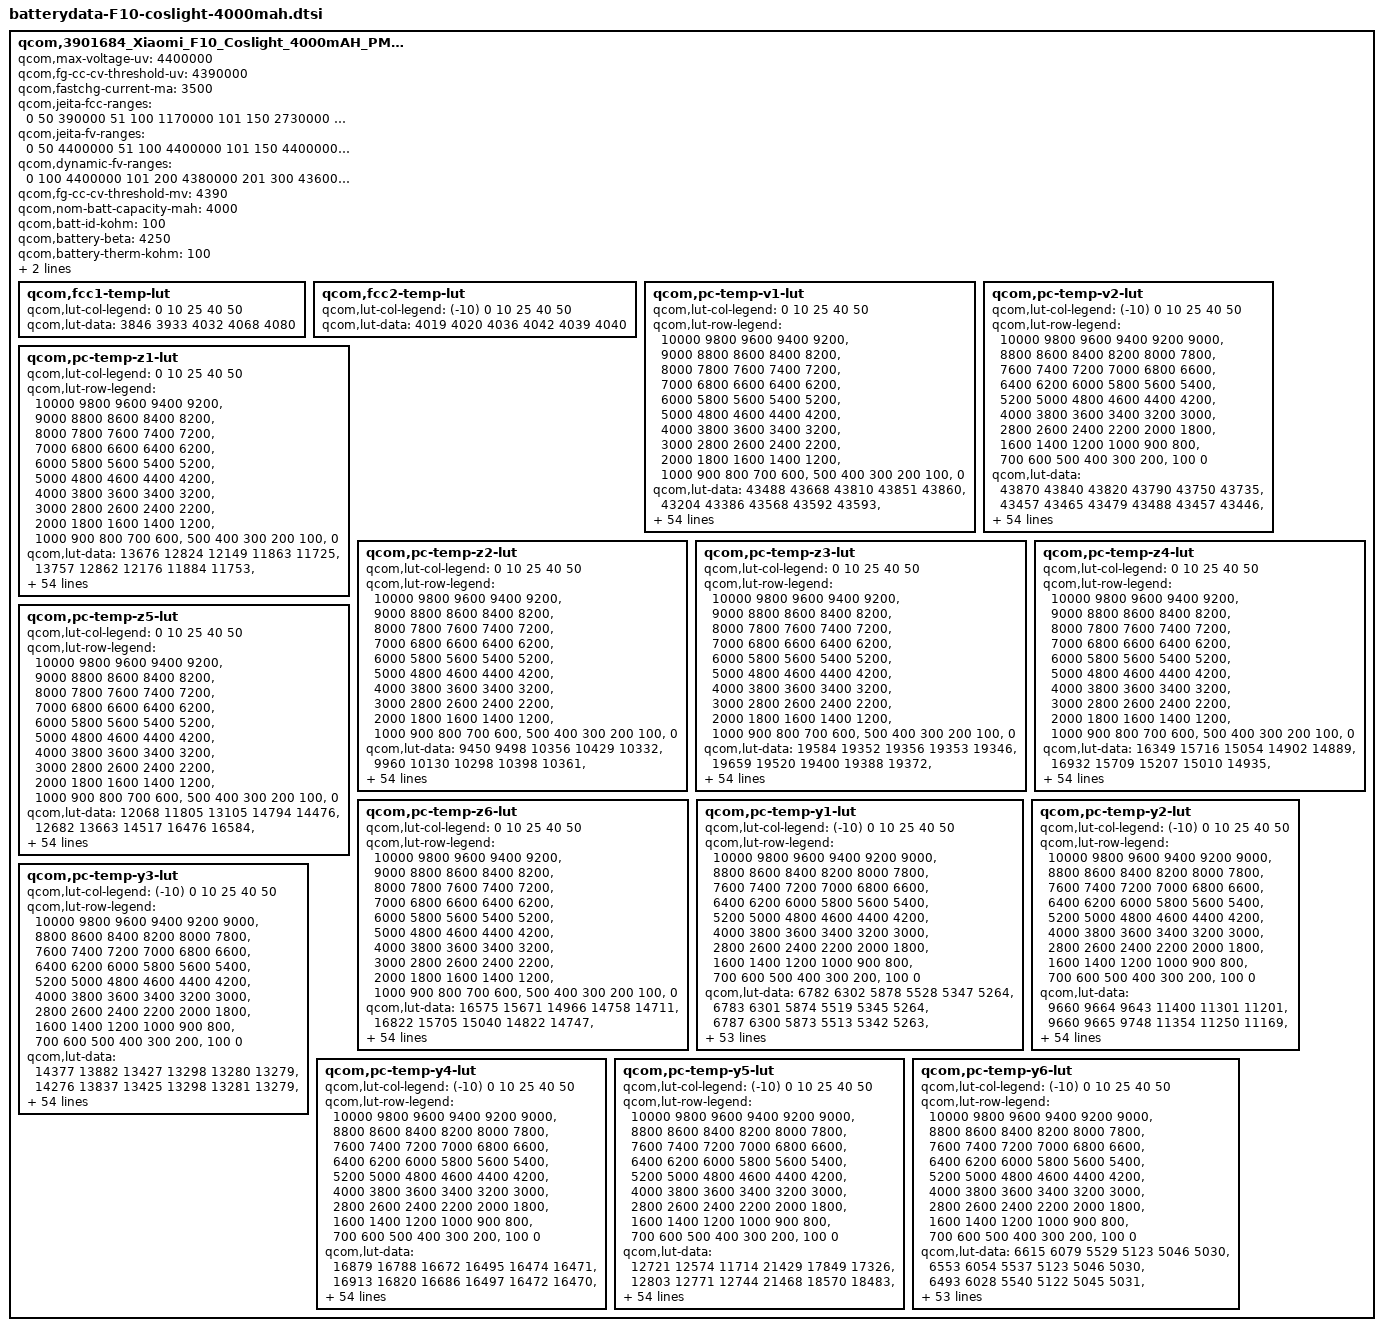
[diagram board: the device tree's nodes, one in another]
qcom,3901684_Xiaomi_F10_Coslight_4000mAH_PM7150 {
    /* 3901684_Xiaomi_F10_Coslight_4000mAH_PM7150_averaged_MasterSlave_Mar20th2019 */
	qcom,max-voltage-uv = <4400000>;
	qcom,fg-cc-cv-threshold-uv = <4390000>;
	qcom,fastchg-current-ma = <3500>;
	qcom,jeita-fcc-ranges = <0  50  390000
				51  100  1170000
				101 150  2730000
				151 450  3500000
				451 580  1950000>;
	qcom,jeita-fv-ranges = <0   50  4400000
				51  100  4400000
				101 150  4400000
				151 450  4400000
				451 580  4100000>;
	qcom,dynamic-fv-ranges = <0    100  4400000
				  101  200  4380000
				  201  300  4360000
				  301  400  4340000
				  401  500  4340000>;
	qcom,fg-cc-cv-threshold-mv = <4390>;
	qcom,nom-batt-capacity-mah = <4000>;
    qcom,batt-id-kohm = <100>;
	qcom,battery-beta = <4250>;
	qcom,battery-therm-kohm = <100>;
	qcom,battery-type = "f10_coslt";
	qcom,qg-batt-profile-ver = <100>;

	qcom,fcc1-temp-lut {
		qcom,lut-col-legend = <0 10 25 40 50>;
		qcom,lut-data = <3846 3933 4032 4068 4080>;
	};

	qcom,fcc2-temp-lut {
		qcom,lut-col-legend = <(-10) 0 10 25 40 50>;
		qcom,lut-data = <4019 4020 4036 4042 4039 4040>;
	};

	qcom,pc-temp-v1-lut {
		qcom,lut-col-legend = <0 10 25 40 50>;
		qcom,lut-row-legend = <10000 9800 9600 9400 9200>,
			<9000 8800 8600 8400 8200>,
			<8000 7800 7600 7400 7200>,
			<7000 6800 6600 6400 6200>,
			<6000 5800 5600 5400 5200>,
			<5000 4800 4600 4400 4200>,
			<4000 3800 3600 3400 3200>,
			<3000 2800 2600 2400 2200>,
			<2000 1800 1600 1400 1200>,
			<1000 900 800 700 600>,
			<500 400 300 200 100>,
			<0>;
		qcom,lut-data = <43488 43668 43810 43851 43860>,
			<43204 43386 43568 43592 43593>,
			<42945 43123 43311 43350 43352>,
			<42701 42877 43059 43112 43117>,
			<42462 42641 42816 42873 42880>,
			<42232 42405 42577 42634 42643>,
			<42008 42173 42339 42398 42407>,
			<41791 41948 42102 42164 42173>,
			<41583 41727 41871 41932 41942>,
			<41392 41514 41644 41702 41714>,
			<41221 41322 41424 41473 41488>,
			<41034 41147 41220 41251 41267>,
			<40791 40954 41030 41034 41048>,
			<40521 40708 40828 40824 40836>,
			<40287 40448 40590 40620 40631>,
			<40082 40232 40355 40424 40434>,
			<39904 40042 40169 40238 40245>,
			<39761 39879 40009 40063 40067>,
			<39639 39743 39857 39894 39896>,
			<39519 39621 39716 39738 39740>,
			<39396 39491 39567 39584 39588>,
			<39275 39356 39372 39388 39398>,
			<39158 39214 39137 39126 39135>,
			<39043 39048 38932 38904 38905>,
			<38935 38866 38758 38764 38769>,
			<38832 38707 38620 38654 38663>,
			<38733 38559 38531 38556 38559>,
			<38640 38442 38465 38470 38456>,
			<38550 38365 38402 38388 38365>,
			<38468 38305 38338 38306 38285>,
			<38396 38261 38279 38231 38214>,
			<38330 38230 38225 38166 38147>,
			<38286 38202 38175 38110 38085>,
			<38262 38174 38127 38057 38026>,
			<38242 38149 38084 38008 37972>,
			<38212 38120 38042 37960 37919>,
			<38172 38091 38003 37913 37866>,
			<38126 38056 37963 37866 37813>,
			<38071 38006 37909 37804 37745>,
			<38004 37936 37827 37716 37652>,
			<37920 37851 37728 37612 37543>,
			<37805 37742 37612 37504 37433>,
			<37672 37611 37477 37380 37309>,
			<37517 37451 37322 37226 37149>,
			<37364 37299 37182 37088 37017>,
			<37251 37194 37084 36995 36937>,
			<37212 37155 37052 36969 36910>,
			<37178 37125 37037 36946 36888>,
			<37148 37101 37015 36926 36869>,
			<37099 37057 36972 36878 36809>,
			<36922 36861 36756 36633 36536>,
			<36490 36427 36327 36199 36099>,
			<35920 35855 35755 35625 35525>,
			<35147 35075 34970 34840 34741>,
			<33910 33851 33747 33621 33517>,
			<30000 30000 30000 30000 30000>;
	};

	qcom,pc-temp-v2-lut {
		qcom,lut-col-legend = <(-10) 0 10 25 40 50>;
		qcom,lut-row-legend = <10000 9800 9600 9400 9200 9000>,
			<8800 8600 8400 8200 8000 7800>,
			<7600 7400 7200 7000 6800 6600>,
			<6400 6200 6000 5800 5600 5400>,
			<5200 5000 4800 4600 4400 4200>,
			<4000 3800 3600 3400 3200 3000>,
			<2800 2600 2400 2200 2000 1800>,
			<1600 1400 1200 1000 900 800>,
			<700 600 500 400 300 200>,
			<100 0>;
		qcom,lut-data = <43870 43840 43820 43790 43750 43735>,
			<43457 43465 43479 43488 43457 43446>,
			<43083 43120 43164 43203 43180 43174>,
			<42755 42809 42879 42939 42922 42918>,
			<42466 42530 42622 42694 42681 42679>,
			<42199 42266 42374 42454 42445 42444>,
			<41950 42011 42125 42215 42209 42207>,
			<41717 41769 41882 41979 41974 41972>,
			<41486 41534 41646 41748 41743 41741>,
			<41254 41301 41414 41521 41515 41514>,
			<41060 41106 41197 41298 41292 41290>,
			<40933 40978 41007 41082 41075 41070>,
			<40811 40857 40821 40869 40862 40854>,
			<40558 40626 40599 40660 40656 40649>,
			<40083 40219 40341 40451 40453 40448>,
			<39699 39874 40110 40251 40259 40256>,
			<39494 39664 39930 40057 40075 40071>,
			<39331 39489 39759 39874 39898 39893>,
			<39161 39308 39564 39714 39732 39726>,
			<38993 39127 39353 39572 39575 39571>,
			<38836 38956 39146 39401 39399 39397>,
			<38687 38791 38939 39162 39176 39180>,
			<38551 38638 38746 38920 38951 38960>,
			<38437 38500 38588 38739 38766 38774>,
			<38339 38375 38451 38586 38602 38607>,
			<38253 38271 38330 38457 38467 38470>,
			<38176 38189 38219 38348 38358 38359>,
			<38106 38119 38125 38252 38263 38261>,
			<38039 38057 38054 38163 38175 38171>,
			<37975 38002 37996 38081 38096 38087>,
			<37913 37951 37943 38008 38025 38015>,
			<37851 37902 37895 37940 37962 37951>,
			<37791 37854 37850 37878 37901 37890>,
			<37730 37806 37806 37824 37837 37825>,
			<37671 37759 37763 37775 37772 37756>,
			<37613 37710 37716 37724 37700 37675>,
			<37556 37657 37665 37673 37619 37573>,
			<37499 37600 37608 37616 37534 37472>,
			<37443 37536 37543 37547 37455 37389>,
			<37388 37466 37471 37468 37376 37314>,
			<37331 37387 37389 37380 37293 37234>,
			<37272 37293 37292 37280 37206 37151>,
			<37209 37190 37188 37162 37094 37039>,
			<37139 37086 37078 37031 36957 36896>,
			<37057 36996 36968 36923 36855 36802>,
			<36948 36906 36845 36854 36804 36754>,
			<36887 36876 36802 36838 36794 36743>,
			<36813 36823 36763 36818 36777 36726>,
			<36723 36763 36717 36783 36745 36693>,
			<36595 36669 36638 36690 36640 36571>,
			<36369 36466 36437 36389 36312 36217>,
			<36002 36054 36001 35863 35794 35699>,
			<35445 35432 35359 35185 35122 35015>,
			<34591 34546 34467 34229 34190 34081>,
			<33142 33098 33118 32916 32929 32822>,
			<28835 28221 27917 27830 28084 28065>;
	};

	qcom,pc-temp-z1-lut {
		qcom,lut-col-legend = <0 10 25 40 50>;
		qcom,lut-row-legend = <10000 9800 9600 9400 9200>,
			<9000 8800 8600 8400 8200>,
			<8000 7800 7600 7400 7200>,
			<7000 6800 6600 6400 6200>,
			<6000 5800 5600 5400 5200>,
			<5000 4800 4600 4400 4200>,
			<4000 3800 3600 3400 3200>,
			<3000 2800 2600 2400 2200>,
			<2000 1800 1600 1400 1200>,
			<1000 900 800 700 600>,
			<500 400 300 200 100>,
			<0>;
		qcom,lut-data = <13676 12824 12149 11863 11725>,
			<13757 12862 12176 11884 11753>,
			<13750 12873 12181 11877 11749>,
			<13740 12865 12182 11863 11738>,
			<13721 12854 12172 11851 11729>,
			<13690 12851 12156 11840 11719>,
			<13677 12847 12147 11833 11712>,
			<13679 12840 12141 11827 11706>,
			<13682 12823 12138 11823 11701>,
			<13676 12805 12140 11819 11699>,
			<13643 12798 12143 11816 11697>,
			<13602 12796 12143 11816 11697>,
			<13561 12791 12143 11815 11698>,
			<13514 12763 12140 11815 11699>,
			<13485 12734 12125 11815 11700>,
			<13464 12731 12111 11817 11701>,
			<13451 12737 12114 11819 11702>,
			<13442 12744 12126 11821 11706>,
			<13420 12757 12136 11823 11709>,
			<13410 12773 12143 11826 11711>,
			<13430 12782 12147 11829 11713>,
			<13452 12789 12149 11833 11715>,
			<13457 12794 12149 11837 11717>,
			<13462 12802 12149 11839 11719>,
			<13467 12813 12147 11840 11722>,
			<13470 12818 12146 11841 11724>,
			<13473 12819 12152 11843 11728>,
			<13476 12820 12166 11849 11732>,
			<13480 12824 12172 11854 11737>,
			<13486 12829 12171 11859 11742>,
			<13491 12835 12170 11864 11746>,
			<13497 12842 12170 11869 11751>,
			<13507 12850 12172 11876 11757>,
			<13534 12865 12175 11881 11762>,
			<13560 12886 12183 11887 11769>,
			<13561 12897 12191 11893 11776>,
			<13549 12904 12198 11899 11781>,
			<13541 12912 12206 11906 11785>,
			<13554 12920 12211 11909 11790>,
			<13582 12930 12215 11912 11797>,
			<13611 12938 12218 11914 11802>,
			<13651 12943 12227 11919 11805>,
			<13680 12949 12236 11926 11808>,
			<13698 12961 12242 11928 11811>,
			<13664 12976 12249 11931 11816>,
			<13665 12976 12271 11939 11820>,
			<13661 12955 12257 11939 11820>,
			<13647 12969 12248 11936 11820>,
			<13654 12983 12270 11940 11823>,
			<13680 12977 12269 11953 11834>,
			<13683 12995 12281 11963 11839>,
			<13680 13009 12271 11965 11851>,
			<13730 13048 12310 11977 11861>,
			<13762 13082 12328 11996 11885>,
			<13762 13082 12328 11996 11885>,
			<13762 13082 12328 11996 11885>;
	};

	qcom,pc-temp-z2-lut {
		qcom,lut-col-legend = <0 10 25 40 50>;
		qcom,lut-row-legend = <10000 9800 9600 9400 9200>,
			<9000 8800 8600 8400 8200>,
			<8000 7800 7600 7400 7200>,
			<7000 6800 6600 6400 6200>,
			<6000 5800 5600 5400 5200>,
			<5000 4800 4600 4400 4200>,
			<4000 3800 3600 3400 3200>,
			<3000 2800 2600 2400 2200>,
			<2000 1800 1600 1400 1200>,
			<1000 900 800 700 600>,
			<500 400 300 200 100>,
			<0>;
		qcom,lut-data = <9450 9498 10356 10429 10332>,
			<9960 10130 10298 10398 10361>,
			<10130 10317 10438 10460 10380>,
			<10228 10298 10522 10512 10414>,
			<10231 10268 10495 10503 10430>,
			<10214 10239 10448 10467 10425>,
			<10198 10209 10409 10424 10408>,
			<10180 10191 10369 10366 10380>,
			<10164 10182 10349 10323 10352>,
			<10163 10177 10347 10331 10342>,
			<10170 10189 10349 10366 10333>,
			<10175 10269 10356 10386 10328>,
			<10164 10324 10371 10396 10332>,
			<10142 10280 10388 10403 10337>,
			<10136 10208 10423 10409 10330>,
			<10214 10194 10460 10415 10305>,
			<10301 10211 10471 10413 10292>,
			<10279 10235 10476 10394 10292>,
			<10174 10266 10484 10380 10299>,
			<10109 10302 10500 10390 10317>,
			<10097 10330 10523 10420 10351>,
			<10090 10354 10554 10483 10426>,
			<10088 10372 10591 10650 10668>,
			<10087 10385 10600 10752 10839>,
			<10087 10394 10566 10630 10700>,
			<10093 10395 10528 10442 10449>,
			<10105 10395 10517 10422 10425>,
			<10119 10397 10510 10482 10589>,
			<10140 10410 10509 10516 10690>,
			<10162 10432 10514 10505 10563>,
			<10181 10444 10521 10483 10369>,
			<10199 10448 10523 10453 10302>,
			<10194 10452 10523 10411 10272>,
			<9887 10459 10526 10396 10259>,
			<9517 10470 10538 10404 10253>,
			<9481 10484 10554 10422 10253>,
			<9559 10506 10573 10452 10281>,
			<9652 10526 10596 10505 10363>,
			<9790 10500 10620 10551 10423>,
			<9948 10408 10646 10592 10461>,
			<9986 10370 10669 10619 10482>,
			<9963 10383 10689 10624 10476>,
			<9939 10358 10701 10620 10464>,
			<9914 10295 10685 10590 10500>,
			<9800 12043 10702 10572 10499>,
			<9756 15846 10733 10546 10435>,
			<9764 13719 10726 10542 10447>,
			<9771 14156 10705 10558 10467>,
			<9740 15920 10736 10601 10544>,
			<9733 15952 10790 10756 10632>,
			<9673 13590 10784 10574 10420>,
			<9525 12191 10699 10408 10277>,
			<9456 11187 10615 10352 10215>,
			<9398 10638 10493 10293 10167>,
			<9398 10638 10493 10293 10167>,
			<9398 10638 10493 10293 10167>;
	};

	qcom,pc-temp-z3-lut {
		qcom,lut-col-legend = <0 10 25 40 50>;
		qcom,lut-row-legend = <10000 9800 9600 9400 9200>,
			<9000 8800 8600 8400 8200>,
			<8000 7800 7600 7400 7200>,
			<7000 6800 6600 6400 6200>,
			<6000 5800 5600 5400 5200>,
			<5000 4800 4600 4400 4200>,
			<4000 3800 3600 3400 3200>,
			<3000 2800 2600 2400 2200>,
			<2000 1800 1600 1400 1200>,
			<1000 900 800 700 600>,
			<500 400 300 200 100>,
			<0>;
		qcom,lut-data = <19584 19352 19356 19353 19346>,
			<19659 19520 19400 19388 19372>,
			<19680 19596 19446 19401 19385>,
			<19689 19617 19467 19408 19394>,
			<19672 19626 19470 19414 19402>,
			<19620 19626 19472 19419 19410>,
			<19593 19624 19473 19421 19413>,
			<19592 19621 19474 19418 19411>,
			<19592 19616 19474 19414 19408>,
			<19593 19609 19469 19410 19404>,
			<19598 19604 19461 19406 19398>,
			<19605 19596 19452 19403 19393>,
			<19619 19590 19442 19401 19390>,
			<19639 19577 19437 19399 19387>,
			<19654 19557 19438 19395 19384>,
			<19672 19543 19438 19389 19380>,
			<19685 19534 19434 19384 19376>,
			<19669 19523 19424 19380 19372>,
			<19620 19503 19417 19376 19367>,
			<19594 19483 19413 19372 19362>,
			<19594 19480 19411 19369 19356>,
			<19597 19484 19415 19370 19356>,
			<19602 19488 19425 19382 19369>,
			<19614 19498 19429 19390 19378>,
			<19621 19514 19426 19381 19369>,
			<19623 19519 19421 19366 19352>,
			<19625 19520 19419 19365 19356>,
			<19625 19519 19417 19373 19394>,
			<19626 19519 19417 19382 19418>,
			<19626 19520 19420 19396 19413>,
			<19625 19519 19423 19408 19403>,
			<19618 19514 19425 19408 19396>,
			<19602 19508 19427 19401 19389>,
			<19467 19502 19427 19395 19382>,
			<19308 19496 19425 19388 19374>,
			<19277 19490 19423 19381 19366>,
			<19271 19485 19418 19375 19359>,
			<19268 19479 19413 19369 19353>,
			<19265 19452 19409 19367 19351>,
			<19263 19394 19406 19367 19352>,
			<19262 19366 19404 19367 19353>,
			<19263 19306 19403 19366 19354>,
			<19263 19262 19402 19364 19355>,
			<19263 19262 19399 19364 19361>,
			<19264 19259 19391 19362 19360>,
			<19264 19257 19381 19355 19350>,
			<19264 19257 19382 19346 19341>,
			<19264 19257 19359 19344 19336>,
			<19264 19257 19354 19340 19323>,
			<19264 19257 19351 19325 19320>,
			<19265 19257 19355 19350 19350>,
			<19269 19258 19360 19361 19360>,
			<19271 19259 19357 19362 19362>,
			<19273 19260 19359 19361 19356>,
			<19273 19260 19359 19361 19356>,
			<19273 19260 19359 19361 19356>;
	};

	qcom,pc-temp-z4-lut {
		qcom,lut-col-legend = <0 10 25 40 50>;
		qcom,lut-row-legend = <10000 9800 9600 9400 9200>,
			<9000 8800 8600 8400 8200>,
			<8000 7800 7600 7400 7200>,
			<7000 6800 6600 6400 6200>,
			<6000 5800 5600 5400 5200>,
			<5000 4800 4600 4400 4200>,
			<4000 3800 3600 3400 3200>,
			<3000 2800 2600 2400 2200>,
			<2000 1800 1600 1400 1200>,
			<1000 900 800 700 600>,
			<500 400 300 200 100>,
			<0>;
		qcom,lut-data = <16349 15716 15054 14902 14889>,
			<16932 15709 15207 15010 14935>,
			<16706 15677 15124 14968 14917>,
			<16405 15498 15032 14902 14871>,
			<16187 15279 14958 14858 14836>,
			<15992 15152 14891 14822 14807>,
			<15824 15056 14842 14794 14782>,
			<15675 14980 14803 14770 14757>,
			<15542 14921 14773 14751 14738>,
			<15426 14872 14750 14737 14730>,
			<15322 14823 14732 14726 14726>,
			<15232 14770 14719 14717 14722>,
			<15158 14740 14709 14710 14717>,
			<15096 14739 14705 14705 14711>,
			<15034 14745 14707 14701 14707>,
			<14957 14742 14709 14698 14704>,
			<14895 14736 14706 14694 14700>,
			<14881 14732 14695 14689 14695>,
			<14889 14729 14684 14683 14691>,
			<14890 14726 14675 14677 14685>,
			<14871 14721 14669 14673 14679>,
			<14845 14708 14687 14684 14686>,
			<14821 14700 14744 14756 14754>,
			<14797 14711 14791 14811 14811>,
			<14778 14738 14827 14823 14820>,
			<14766 14759 14849 14829 14824>,
			<14757 14791 14841 14824 14815>,
			<14751 14811 14814 14796 14759>,
			<14747 14807 14789 14765 14717>,
			<14744 14792 14768 14737 14708>,
			<14743 14776 14749 14712 14702>,
			<14743 14757 14732 14700 14696>,
			<14748 14738 14716 14693 14690>,
			<14879 14723 14706 14689 14686>,
			<15037 14710 14699 14687 14685>,
			<15057 14700 14694 14686 14684>,
			<15042 14691 14690 14684 14682>,
			<15027 14685 14686 14681 14680>,
			<15015 14706 14686 14680 14680>,
			<15003 14765 14688 14687 14689>,
			<14995 14791 14690 14694 14698>,
			<14990 14849 14688 14690 14693>,
			<14984 14892 14685 14682 14683>,
			<14973 14889 14684 14683 14686>,
			<14915 14861 14675 14677 14680>,
			<14896 14837 14658 14658 14657>,
			<14892 14830 14648 14656 14655>,
			<14886 14824 14657 14644 14644>,
			<14878 14815 14651 14631 14635>,
			<14873 14811 14650 14638 14629>,
			<14874 14821 14664 14644 14646>,
			<14903 14843 14674 14650 14653>,
			<14923 14854 14683 14655 14659>,
			<14946 14870 14688 14663 14671>,
			<14946 14870 14688 14663 14671>,
			<14946 14870 14688 14663 14671>;
	};

	qcom,pc-temp-z5-lut {
		qcom,lut-col-legend = <0 10 25 40 50>;
		qcom,lut-row-legend = <10000 9800 9600 9400 9200>,
			<9000 8800 8600 8400 8200>,
			<8000 7800 7600 7400 7200>,
			<7000 6800 6600 6400 6200>,
			<6000 5800 5600 5400 5200>,
			<5000 4800 4600 4400 4200>,
			<4000 3800 3600 3400 3200>,
			<3000 2800 2600 2400 2200>,
			<2000 1800 1600 1400 1200>,
			<1000 900 800 700 600>,
			<500 400 300 200 100>,
			<0>;
		qcom,lut-data = <12068 11805 13105 14794 14476>,
			<12682 13663 14517 16476 16584>,
			<13059 14803 16164 17427 17425>,
			<13339 15366 17399 18166 18528>,
			<13521 15816 18166 19089 19689>,
			<13671 16354 18845 20011 20860>,
			<13821 16934 19850 20564 21968>,
			<14032 17605 21219 20921 23164>,
			<14296 18400 22511 21323 24051>,
			<14526 19246 23717 22058 24084>,
			<14722 20355 24682 23149 23878>,
			<14977 22381 25011 24202 23807>,
			<15447 23829 25072 25332 24409>,
			<16055 24330 25398 26277 25312>,
			<16684 24777 28353 26744 25951>,
			<18399 25088 31787 26886 26556>,
			<20005 25071 31433 26861 27134>,
			<19477 24647 29122 27312 27751>,
			<17227 22780 28219 28003 28165>,
			<16028 20648 30088 28951 28372>,
			<16307 20698 33450 30371 28789>,
			<16872 22949 39426 32478 29794>,
			<17731 26251 48734 36284 32673>,
			<19374 35028 51577 38412 34634>,
			<21171 48727 43042 31788 29235>,
			<22986 53682 32940 21734 19795>,
			<25142 52124 28773 19776 18837>,
			<27702 49566 26042 19634 24638>,
			<31349 48095 25391 19762 28758>,
			<33917 46489 25900 23615 29254>,
			<34214 44620 26850 29088 29587>,
			<34319 41836 28704 31752 30507>,
			<33970 39347 31933 33664 32360>,
			<24494 38187 35347 34897 33251>,
			<13047 37314 39698 35771 33141>,
			<11330 36519 42444 36291 32872>,
			<11293 35785 42135 35950 32238>,
			<11280 34945 41098 34863 30963>,
			<11283 32441 39932 34083 30210>,
			<11292 27797 38401 33668 29975>,
			<11306 25841 36924 33125 29744>,
			<11357 17804 35863 30938 29041>,
			<11396 11760 34701 28209 28242>,
			<11420 11783 32202 28711 31717>,
			<11663 11863 31291 28853 32969>,
			<11696 11770 30257 27411 27639>,
			<11631 11755 32521 22995 22679>,
			<11593 11707 21689 24268 23072>,
			<11588 11640 21033 26370 21154>,
			<11606 11672 21179 20038 21192>,
			<11676 11783 19812 26887 31299>,
			<11747 11696 18623 25719 28100>,
			<11603 11583 17171 23479 24321>,
			<11481 11457 16600 20465 18831>,
			<11481 11457 16600 20465 18831>,
			<11481 11457 16600 20465 18831>;
	};

	qcom,pc-temp-z6-lut {
		qcom,lut-col-legend = <0 10 25 40 50>;
		qcom,lut-row-legend = <10000 9800 9600 9400 9200>,
			<9000 8800 8600 8400 8200>,
			<8000 7800 7600 7400 7200>,
			<7000 6800 6600 6400 6200>,
			<6000 5800 5600 5400 5200>,
			<5000 4800 4600 4400 4200>,
			<4000 3800 3600 3400 3200>,
			<3000 2800 2600 2400 2200>,
			<2000 1800 1600 1400 1200>,
			<1000 900 800 700 600>,
			<500 400 300 200 100>,
			<0>;
		qcom,lut-data = <16575 15671 14966 14758 14711>,
			<16822 15705 15040 14822 14747>,
			<16676 15702 15015 14806 14743>,
			<16479 15603 14983 14780 14728>,
			<16322 15474 14946 14762 14716>,
			<16172 15393 14908 14746 14706>,
			<16049 15328 14880 14732 14696>,
			<15953 15275 14857 14718 14684>,
			<15872 15232 14838 14706 14673>,
			<15802 15194 14822 14697 14666>,
			<15740 15156 14808 14689 14661>,
			<15683 15120 14797 14683 14656>,
			<15626 15090 14788 14679 14652>,
			<15573 15067 14781 14675 14648>,
			<15530 15050 14778 14671 14644>,
			<15494 15040 14775 14667 14641>,
			<15463 15033 14771 14662 14637>,
			<15436 15027 14762 14657 14633>,
			<15413 15020 14756 14653 14628>,
			<15400 15014 14752 14649 14623>,
			<15392 15013 14750 14646 14618>,
			<15387 15014 14760 14652 14622>,
			<15387 15015 14791 14691 14659>,
			<15387 15025 14815 14718 14688>,
			<15387 15048 14830 14718 14686>,
			<15386 15065 14839 14716 14682>,
			<15385 15081 14836 14712 14679>,
			<15386 15090 14825 14706 14677>,
			<15390 15089 14817 14700 14673>,
			<15394 15087 14811 14696 14668>,
			<15394 15084 14806 14693 14661>,
			<15394 15077 14802 14689 14656>,
			<15394 15068 14797 14683 14650>,
			<15388 15062 14795 14679 14646>,
			<15379 15057 14793 14676 14642>,
			<15376 15054 14791 14673 14638>,
			<15374 15053 14790 14670 14635>,
			<15373 15053 14789 14667 14631>,
			<15376 15054 14789 14666 14630>,
			<15382 15057 14791 14670 14635>,
			<15387 15059 14793 14675 14641>,
			<15393 15060 14795 14673 14639>,
			<15401 15063 14798 14671 14637>,
			<15412 15074 14800 14672 14641>,
			<15409 15072 14797 14670 14639>,
			<15403 15065 14788 14659 14625>,
			<15404 15063 14785 14654 14620>,
			<15401 15062 14778 14648 14613>,
			<15400 15060 14776 14641 14603>,
			<15402 15065 14777 14639 14600>,
			<15415 15079 14790 14657 14625>,
			<15441 15098 14803 14669 14637>,
			<15466 15115 14811 14676 14644>,
			<15503 15144 14824 14684 14651>,
			<15503 15144 14824 14684 14651>,
			<15503 15144 14824 14684 14651>;
	};

	qcom,pc-temp-y1-lut {
		qcom,lut-col-legend = <(-10) 0 10 25 40 50>;
		qcom,lut-row-legend = <10000 9800 9600 9400 9200 9000>,
			<8800 8600 8400 8200 8000 7800>,
			<7600 7400 7200 7000 6800 6600>,
			<6400 6200 6000 5800 5600 5400>,
			<5200 5000 4800 4600 4400 4200>,
			<4000 3800 3600 3400 3200 3000>,
			<2800 2600 2400 2200 2000 1800>,
			<1600 1400 1200 1000 900 800>,
			<700 600 500 400 300 200>,
			<100 0>;
		qcom,lut-data = <6782 6302 5878 5528 5347 5264>,
			<6783 6301 5874 5519 5345 5264>,
			<6787 6300 5873 5513 5342 5263>,
			<6791 6298 5874 5509 5340 5262>,
			<6794 6297 5876 5507 5338 5261>,
			<6797 6295 5878 5507 5337 5259>,
			<6808 6294 5884 5510 5335 5256>,
			<6824 6293 5891 5514 5335 5253>,
			<6825 6291 5891 5514 5333 5252>,
			<6816 6286 5887 5509 5331 5251>,
			<6811 6283 5885 5507 5330 5250>,
			<6815 6284 5887 5510 5330 5249>,
			<6819 6287 5890 5515 5330 5249>,
			<6827 6290 5895 5514 5329 5248>,
			<6854 6294 5902 5508 5327 5248>,
			<6869 6296 5906 5505 5326 5247>,
			<6859 6297 5904 5509 5327 5247>,
			<6844 6299 5902 5515 5329 5248>,
			<6845 6304 5903 5518 5329 5248>,
			<6866 6320 5904 5519 5330 5250>,
			<6879 6331 5905 5520 5330 5251>,
			<6863 6337 5904 5521 5332 5252>,
			<6840 6341 5904 5522 5334 5253>,
			<6839 6339 5907 5523 5336 5255>,
			<6848 6329 5911 5524 5339 5257>,
			<6859 6321 5913 5524 5341 5260>,
			<6873 6318 5908 5524 5342 5262>,
			<6885 6316 5903 5525 5344 5265>,
			<6883 6315 5905 5527 5346 5268>,
			<6864 6313 5913 5528 5348 5272>,
			<6849 6311 5915 5530 5352 5276>,
			<6841 6307 5913 5533 5357 5279>,
			<6835 6304 5912 5535 5362 5282>,
			<6837 6304 5913 5537 5363 5284>,
			<6848 6305 5915 5539 5364 5287>,
			<6854 6306 5916 5540 5365 5288>,
			<6842 6307 5911 5541 5367 5290>,
			<6826 6308 5907 5542 5369 5292>,
			<6827 6309 5906 5542 5371 5293>,
			<6844 6308 5906 5541 5373 5295>,
			<6855 6307 5906 5543 5374 5296>,
			<6842 6313 5913 5549 5376 5298>,
			<6830 6319 5918 5551 5377 5302>,
			<6857 6313 5921 5552 5380 5309>,
			<6861 6316 5928 5555 5386 5314>,
			<6935 6379 5949 5562 5392 5318>,
			<6903 6377 5952 5571 5392 5318>,
			<6914 6354 5954 5570 5394 5318>,
			<6935 6362 5951 5565 5393 5317>,
			<6950 6380 5967 5569 5393 5317>,
			<6936 6378 5973 5576 5397 5322>,
			<7003 6410 5978 5586 5403 5330>,
			<7023 6448 6012 5609 5419 5340>,
			<7114 6478 6045 5631 5434 5352>,
			<7114 6478 6045 5631 5434 5352>,
			<7114 6478 6045 5631 5434 5352>;
	};

	qcom,pc-temp-y2-lut {
		qcom,lut-col-legend = <(-10) 0 10 25 40 50>;
		qcom,lut-row-legend = <10000 9800 9600 9400 9200 9000>,
			<8800 8600 8400 8200 8000 7800>,
			<7600 7400 7200 7000 6800 6600>,
			<6400 6200 6000 5800 5600 5400>,
			<5200 5000 4800 4600 4400 4200>,
			<4000 3800 3600 3400 3200 3000>,
			<2800 2600 2400 2200 2000 1800>,
			<1600 1400 1200 1000 900 800>,
			<700 600 500 400 300 200>,
			<100 0>;
		qcom,lut-data = <9660 9664 9643 11400 11301 11201>,
			<9660 9665 9748 11354 11250 11169>,
			<9661 9667 9949 11308 11201 11135>,
			<9661 9669 10162 11263 11154 11100>,
			<9662 9671 10340 11220 11112 11067>,
			<9662 9673 10434 11177 11075 11038>,
			<9663 9676 10464 11134 11043 11011>,
			<9663 9678 10486 11093 11015 10985>,
			<9663 9679 10514 11065 10988 10955>,
			<9664 9679 10550 11043 10960 10922>,
			<9664 9679 10594 11026 10948 10899>,
			<9665 9681 10678 11010 10965 10886>,
			<9665 9683 10775 10999 10987 10878>,
			<9665 9683 10833 11005 10985 10879>,
			<9665 9679 10879 11039 10967 10888>,
			<9665 9677 10925 11082 10960 10893>,
			<9665 9676 10989 11140 10988 10907>,
			<9665 9675 11042 11211 11040 10931>,
			<9665 9675 11053 11297 11121 10978>,
			<9665 9675 11053 11398 11250 11086>,
			<9665 9675 11048 11432 11323 11166>,
			<9665 9675 10794 11380 11329 11226>,
			<9665 9674 10479 11327 11318 11265>,
			<9664 9674 10424 11335 11307 11248>,
			<9664 9674 10398 11368 11288 11201>,
			<9664 9673 10349 11396 11284 11184>,
			<9664 9672 10059 11416 11302 11197>,
			<9664 9671 9802 11433 11323 11216>,
			<9664 9670 9779 11443 11341 11239>,
			<9664 9669 9765 11451 11375 11271>,
			<9664 9668 9749 11456 11410 11302>,
			<9664 9667 9728 11462 11452 11343>,
			<9663 9667 9710 11467 11480 11376>,
			<9663 9666 9701 11466 11475 11380>,
			<9663 9665 9694 11462 11462 11367>,
			<9663 9665 9690 11455 11448 11350>,
			<9663 9664 9686 11433 11427 11304>,
			<9663 9663 9682 11403 11403 11250>,
			<9662 9663 9678 11369 11370 11209>,
			<9662 9662 9675 11330 11335 11176>,
			<9662 9662 9672 11290 11318 11171>,
			<9662 9661 9669 11245 11288 11197>,
			<9661 9661 9667 11177 11257 11184>,
			<9661 9661 9664 11081 11215 11123>,
			<9660 9660 9663 11000 11116 11034>,
			<9660 9660 9663 10934 11068 10915>,
			<9660 10938 9662 10945 11098 10909>,
			<9660 9866 9662 10938 11117 10940>,
			<9659 9659 9661 10942 11138 11017>,
			<9659 9659 9661 10956 11152 10981>,
			<9658 9659 9660 10862 11113 10886>,
			<9658 9658 9659 10706 10976 10822>,
			<9657 9657 9658 10554 10898 10737>,
			<9654 9657 9657 10421 10803 10620>,
			<9654 9657 9657 10421 10803 10620>,
			<9654 9657 9657 10421 10803 10620>;
	};

	qcom,pc-temp-y3-lut {
		qcom,lut-col-legend = <(-10) 0 10 25 40 50>;
		qcom,lut-row-legend = <10000 9800 9600 9400 9200 9000>,
			<8800 8600 8400 8200 8000 7800>,
			<7600 7400 7200 7000 6800 6600>,
			<6400 6200 6000 5800 5600 5400>,
			<5200 5000 4800 4600 4400 4200>,
			<4000 3800 3600 3400 3200 3000>,
			<2800 2600 2400 2200 2000 1800>,
			<1600 1400 1200 1000 900 800>,
			<700 600 500 400 300 200>,
			<100 0>;
		qcom,lut-data = <14377 13882 13427 13298 13280 13279>,
			<14276 13837 13425 13298 13281 13279>,
			<14179 13793 13422 13299 13282 13280>,
			<14089 13752 13418 13300 13283 13281>,
			<14010 13714 13415 13301 13284 13282>,
			<13945 13680 13412 13302 13285 13282>,
			<13896 13651 13408 13303 13286 13282>,
			<13854 13623 13405 13304 13286 13283>,
			<13802 13594 13406 13305 13287 13283>,
			<13736 13560 13412 13306 13287 13284>,
			<13705 13538 13414 13307 13287 13285>,
			<13706 13529 13394 13309 13290 13286>,
			<13710 13522 13368 13310 13293 13286>,
			<13700 13509 13366 13311 13293 13287>,
			<13661 13485 13370 13312 13294 13289>,
			<13639 13466 13371 13312 13294 13291>,
			<13639 13453 13368 13310 13295 13291>,
			<13639 13442 13363 13307 13297 13292>,
			<13640 13433 13356 13307 13297 13292>,
			<13643 13425 13347 13307 13295 13293>,
			<13645 13420 13340 13307 13293 13293>,
			<13645 13418 13334 13303 13290 13289>,
			<13645 13417 13330 13298 13287 13285>,
			<13646 13416 13327 13295 13285 13282>,
			<13652 13414 13324 13294 13283 13280>,
			<13660 13414 13319 13293 13282 13279>,
			<13675 13422 13296 13293 13282 13279>,
			<13693 13435 13275 13292 13282 13280>,
			<13712 13448 13275 13292 13282 13279>,
			<13732 13465 13280 13291 13282 13278>,
			<13752 13483 13286 13291 13282 13278>,
			<13774 13501 13296 13291 13282 13278>,
			<13798 13521 13308 13291 13283 13279>,
			<13822 13543 13320 13291 13283 13279>,
			<13845 13569 13331 13292 13283 13280>,
			<13871 13595 13344 13292 13283 13280>,
			<13900 13622 13357 13293 13283 13279>,
			<13932 13650 13374 13293 13283 13279>,
			<13966 13682 13392 13294 13283 13280>,
			<14004 13720 13415 13294 13284 13282>,
			<14043 13758 13443 13295 13284 13283>,
			<14083 13797 13480 13296 13285 13283>,
			<14127 13838 13524 13296 13284 13283>,
			<14183 13882 13577 13295 13282 13280>,
			<14247 13935 13629 13297 13283 13283>,
			<14240 13947 13620 13298 13287 13286>,
			<14296 13698 13672 13304 13291 13289>,
			<14360 13985 13715 13309 13294 13291>,
			<14429 14092 13758 13314 13295 13292>,
			<14516 14141 13796 13317 13294 13290>,
			<14609 14202 13840 13314 13291 13287>,
			<14738 14280 13919 13316 13292 13289>,
			<14958 14419 14080 13330 13298 13294>,
			<15801 14628 14268 13356 13307 13303>,
			<15801 14628 14268 13356 13307 13303>,
			<15801 14628 14268 13356 13307 13303>;
	};

	qcom,pc-temp-y4-lut {
		qcom,lut-col-legend = <(-10) 0 10 25 40 50>;
		qcom,lut-row-legend = <10000 9800 9600 9400 9200 9000>,
			<8800 8600 8400 8200 8000 7800>,
			<7600 7400 7200 7000 6800 6600>,
			<6400 6200 6000 5800 5600 5400>,
			<5200 5000 4800 4600 4400 4200>,
			<4000 3800 3600 3400 3200 3000>,
			<2800 2600 2400 2200 2000 1800>,
			<1600 1400 1200 1000 900 800>,
			<700 600 500 400 300 200>,
			<100 0>;
		qcom,lut-data = <16879 16788 16672 16495 16474 16471>,
			<16913 16820 16686 16497 16472 16470>,
			<16954 16868 16709 16499 16471 16469>,
			<16994 16917 16734 16503 16470 16469>,
			<17028 16956 16754 16505 16469 16468>,
			<17047 16971 16762 16506 16469 16468>,
			<17053 16966 16761 16507 16469 16468>,
			<17058 16959 16758 16507 16470 16468>,
			<17072 16962 16753 16507 16471 16468>,
			<17115 16985 16739 16510 16473 16469>,
			<17151 17017 16733 16513 16475 16470>,
			<17177 17082 16802 16517 16476 16472>,
			<17199 17148 16892 16522 16477 16474>,
			<17149 17114 16886 16530 16480 16477>,
			<16924 16925 16820 16543 16486 16479>,
			<16789 16807 16786 16560 16494 16482>,
			<16781 16793 16786 16583 16503 16488>,
			<16776 16785 16786 16609 16514 16497>,
			<16762 16767 16773 16633 16537 16514>,
			<16733 16738 16729 16656 16572 16540>,
			<16708 16707 16683 16661 16585 16551>,
			<16689 16673 16641 16604 16559 16537>,
			<16674 16641 16602 16532 16520 16515>,
			<16668 16620 16575 16501 16492 16493>,
			<16665 16604 16552 16479 16466 16469>,
			<16663 16597 16547 16473 16459 16461>,
			<16661 16598 16567 16473 16459 16461>,
			<16658 16600 16588 16473 16460 16461>,
			<16658 16599 16590 16474 16464 16463>,
			<16658 16597 16587 16477 16470 16471>,
			<16659 16597 16584 16479 16478 16479>,
			<16661 16602 16580 16481 16489 16489>,
			<16665 16609 16577 16482 16496 16498>,
			<16669 16615 16579 16485 16496 16502>,
			<16674 16621 16585 16489 16496 16504>,
			<16680 16627 16591 16492 16494 16502>,
			<16688 16635 16599 16496 16480 16482>,
			<16699 16643 16606 16497 16469 16465>,
			<16713 16650 16615 16497 16469 16467>,
			<16733 16657 16625 16497 16470 16473>,
			<16756 16658 16630 16498 16473 16482>,
			<16782 16648 16633 16502 16486 16496>,
			<16809 16641 16640 16502 16484 16492>,
			<16837 16645 16657 16499 16463 16459>,
			<16839 16654 16661 16499 16457 16450>,
			<16759 16646 16641 16504 16470 16478>,
			<16772 16628 16676 16526 16496 16511>,
			<16787 16679 16711 16556 16530 16547>,
			<16802 16724 16754 16599 16567 16580>,
			<16815 16752 16798 16623 16569 16567>,
			<16815 16755 16806 16578 16505 16494>,
			<16812 16727 16770 16557 16489 16485>,
			<16812 16713 16759 16588 16504 16490>,
			<17025 16736 16768 16641 16549 16532>,
			<17025 16736 16768 16641 16549 16532>,
			<17025 16736 16768 16641 16549 16532>;
	};

	qcom,pc-temp-y5-lut {
		qcom,lut-col-legend = <(-10) 0 10 25 40 50>;
		qcom,lut-row-legend = <10000 9800 9600 9400 9200 9000>,
			<8800 8600 8400 8200 8000 7800>,
			<7600 7400 7200 7000 6800 6600>,
			<6400 6200 6000 5800 5600 5400>,
			<5200 5000 4800 4600 4400 4200>,
			<4000 3800 3600 3400 3200 3000>,
			<2800 2600 2400 2200 2000 1800>,
			<1600 1400 1200 1000 900 800>,
			<700 600 500 400 300 200>,
			<100 0>;
		qcom,lut-data = <12721 12574 11714 21429 17849 17326>,
			<12803 12771 12744 21468 18570 18483>,
			<12973 12973 13871 21399 19027 19206>,
			<13189 13168 14956 21254 19275 19579>,
			<13409 13341 15860 21065 19364 19684>,
			<13589 13478 16444 20864 19346 19604>,
			<13803 13603 16726 20617 19085 19118>,
			<14004 13701 16946 20324 18627 18469>,
			<13953 13633 17394 19990 18109 18219>,
			<13560 13249 18181 19475 17401 18096>,
			<13346 13035 18531 18914 17098 17935>,
			<16692 14826 17047 18303 17681 17409>,
			<21397 17350 15159 17695 18405 16847>,
			<21122 17566 15776 17243 18227 16892>,
			<16716 16573 19036 16876 17214 17278>,
			<14214 15953 21218 16494 16444 17440>,
			<14420 15709 21885 15920 16026 16823>,
			<14750 15451 22333 15481 15750 15991>,
			<14946 15489 22768 16182 15657 15641>,
			<15097 15640 23194 18832 15554 15368>,
			<15146 15708 23409 21213 15661 15417>,
			<14527 15641 22174 23216 18892 18007>,
			<13647 15495 20561 24650 22340 20867>,
			<13316 15058 20391 24959 22589 21330>,
			<13135 13998 20610 24883 22461 21488>,
			<13070 13366 20235 24666 22317 21470>,
			<13208 13127 16260 24207 21653 20938>,
			<13403 12975 12631 23788 20872 20117>,
			<13492 13087 12510 23613 20523 18961>,
			<13645 13475 12782 23492 20220 17437>,
			<13684 13773 13053 23474 20182 16975>,
			<13637 13915 13460 23659 20645 17317>,
			<13575 14033 13893 23911 21325 17927>,
			<13500 14217 14256 24102 22017 19281>,
			<13394 14508 14596 24301 22817 21299>,
			<13316 14686 14738 24426 23538 21921>,
			<13259 14729 14814 24425 24273 21838>,
			<13212 14767 14871 24242 24690 21762>,
			<13186 14838 14910 23570 24550 22305>,
			<13175 14950 14929 22512 24174 23302>,
			<13194 15035 14908 21807 23757 23520>,
			<13269 15017 14837 21333 22982 23259>,
			<13372 14792 14654 20383 21854 22780>,
			<13650 13967 14272 19178 20572 21652>,
			<14000 13924 14708 18853 19751 21581>,
			<14438 13886 14499 18363 18848 17827>,
			<14630 18063 14599 18826 18806 16858>,
			<14803 14875 15139 18676 17866 15998>,
			<15217 14466 15877 18734 17316 15791>,
			<15861 15167 16467 19013 17053 15568>,
			<15548 15750 16499 19379 18533 17169>,
			<14682 14807 15294 19310 19743 17890>,
			<14145 13958 14232 19167 20475 18350>,
			<12246 13816 13790 20861 24035 24284>,
			<12246 13816 13790 20861 24035 24284>,
			<12246 13816 13790 20861 24035 24284>;
	};

	qcom,pc-temp-y6-lut {
		qcom,lut-col-legend = <(-10) 0 10 25 40 50>;
		qcom,lut-row-legend = <10000 9800 9600 9400 9200 9000>,
			<8800 8600 8400 8200 8000 7800>,
			<7600 7400 7200 7000 6800 6600>,
			<6400 6200 6000 5800 5600 5400>,
			<5200 5000 4800 4600 4400 4200>,
			<4000 3800 3600 3400 3200 3000>,
			<2800 2600 2400 2200 2000 1800>,
			<1600 1400 1200 1000 900 800>,
			<700 600 500 400 300 200>,
			<100 0>;
		qcom,lut-data = <6615 6079 5529 5123 5046 5030>,
			<6553 6054 5537 5123 5046 5030>,
			<6493 6028 5540 5122 5045 5031>,
			<6438 6001 5538 5121 5045 5031>,
			<6387 5974 5534 5120 5045 5031>,
			<6342 5947 5527 5119 5045 5031>,
			<6301 5918 5517 5119 5046 5031>,
			<6266 5889 5504 5118 5046 5031>,
			<6233 5865 5494 5118 5046 5031>,
			<6201 5843 5484 5118 5047 5032>,
			<6186 5834 5478 5119 5047 5033>,
			<6190 5839 5478 5119 5049 5034>,
			<6194 5846 5477 5121 5051 5035>,
			<6174 5832 5472 5123 5053 5036>,
			<6087 5766 5457 5126 5054 5038>,
			<6035 5722 5449 5130 5057 5040>,
			<6033 5715 5447 5136 5060 5043>,
			<6031 5711 5446 5143 5064 5045>,
			<6028 5702 5439 5149 5070 5050>,
			<6024 5690 5420 5155 5079 5058>,
			<6020 5679 5402 5156 5082 5061>,
			<6014 5672 5385 5137 5072 5055>,
			<6010 5666 5370 5113 5058 5045>,
			<6010 5663 5364 5103 5049 5037>,
			<6013 5661 5360 5097 5040 5028>,
			<6018 5661 5358 5095 5038 5026>,
			<6028 5669 5360 5095 5038 5026>,
			<6042 5684 5364 5096 5039 5026>,
			<6055 5697 5370 5097 5040 5027>,
			<6069 5710 5382 5099 5043 5029>,
			<6085 5725 5395 5101 5046 5031>,
			<6102 5743 5409 5103 5049 5035>,
			<6121 5763 5424 5105 5052 5038>,
			<6140 5785 5442 5108 5053 5040>,
			<6160 5808 5462 5111 5053 5041>,
			<6182 5832 5484 5114 5053 5041>,
			<6205 5855 5508 5118 5050 5035>,
			<6231 5880 5534 5121 5047 5030>,
			<6261 5909 5562 5123 5047 5031>,
			<6297 5941 5593 5126 5048 5035>,
			<6334 5973 5627 5130 5051 5039>,
			<6372 6002 5667 5135 5055 5044>,
			<6414 6034 5714 5141 5054 5042>,
			<6470 6071 5767 5146 5049 5032>,
			<6529 6121 5816 5155 5050 5033>,
			<6526 6133 5808 5159 5057 5043>,
			<6575 6177 5860 5175 5068 5055>,
			<6632 6220 5906 5191 5079 5067>,
			<6692 6272 5953 5210 5091 5077>,
			<6769 6321 5999 5221 5091 5072>,
			<6846 6374 6041 5211 5071 5050>,
			<6958 6432 6098 5221 5069 5049>,
			<7145 6543 6232 5271 5081 5056>,
			<7921 6727 6391 5340 5104 5078>,
			<7921 6727 6391 5340 5104 5078>,
			<7921 6727 6391 5340 5104 5078>;
	};

};
